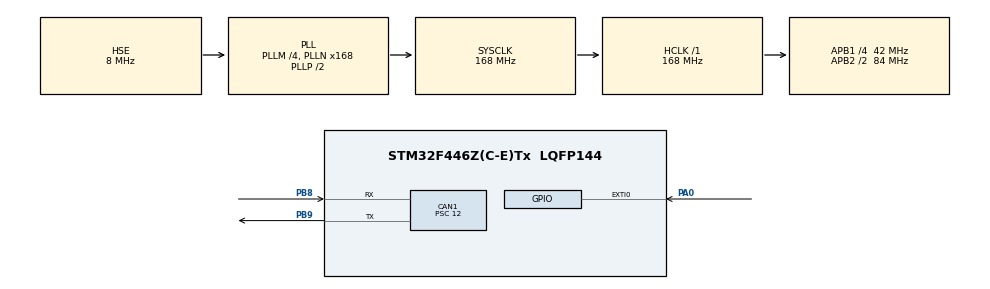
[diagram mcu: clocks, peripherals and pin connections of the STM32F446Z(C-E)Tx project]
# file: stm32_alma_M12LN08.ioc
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CAN1.BS1=CAN_BS1_11TQ
CAN1.BS2=CAN_BS2_2TQ
CAN1.CalculateBaudRate=250000
CAN1.CalculateTimeBit=4000
CAN1.CalculateTimeQuantum=285.7142857142857
CAN1.Prescaler=12
Mcu.Family=STM32F4
Mcu.Name=STM32F446Z(C-E)Tx
Mcu.Package=LQFP144
NVIC.CAN1_RX0_IRQn=true\:0\:0\:false\:false\:true\:true\:true\:true
NVIC.EXTI0_IRQn=true\:0\:0\:false\:false\:true\:true\:true\:true
NVIC.PriorityGroup=NVIC_PRIORITYGROUP_0
PA0-WKUP.Signal=GPXTI0
PA13.Mode=Serial_Wire
PA13.Signal=SYS_JTMS-SWDIO
PA14.Mode=Serial_Wire
PA14.Signal=SYS_JTCK-SWCLK
PB8.Mode=CAN_Activate
PB8.Signal=CAN1_RX
PB9.Mode=CAN_Activate
PB9.Signal=CAN1_TX
PH0-OSC_IN.Mode=HSE-External-Oscillator
PH0-OSC_IN.Signal=RCC_OSC_IN
PH1-OSC_OUT.Mode=HSE-External-Oscillator
PH1-OSC_OUT.Signal=RCC_OSC_OUT
ProjectManager.HeapSize=0x200
ProjectManager.StackSize=0x400
ProjectManager.TargetToolchain=STM32CubeIDE
RCC.AHBFreq_Value=168000000
RCC.APB1CLKDivider=RCC_HCLK_DIV4
RCC.APB1Freq_Value=42000000
RCC.APB1TimFreq_Value=84000000
RCC.APB2CLKDivider=RCC_HCLK_DIV2
RCC.APB2Freq_Value=84000000
RCC.APB2TimFreq_Value=168000000
RCC.CortexFreq_Value=168000000
RCC.HCLKFreq_Value=168000000
RCC.HSE_VALUE=8000000
RCC.PLLM=4
RCC.PLLN=168
RCC.PLLSourceVirtual=RCC_PLLSOURCE_HSE
RCC.SYSCLKFreq_VALUE=168000000
RCC.SYSCLKSource=RCC_SYSCLKSOURCE_PLLCLK
RCC.USBFreq_Value=168000000
RCC.VCOOutputFreq_Value=336000000
board=custom

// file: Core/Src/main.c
/* USER CODE BEGIN Header */
/**
  ******************************************************************************
  * @file           : main.c
  * @brief          : Main program body
  ******************************************************************************
  * @attention
  *
  * Copyright (c) 2024 STMicroelectronics.
  * All rights reserved.
  *
  * This software is licensed under terms that can be found in the LICENSE file
  * in the root directory of this software component.
  * If no LICENSE file comes with this software, it is provided AS-IS.
  *
  ******************************************************************************
  */
/* USER CODE END Header */
#include "main.h"

/* USER CODE BEGIN PD */
CAN_FilterTypeDef sFilterConfig;

/* USER CODE END PD */

CAN_HandleTypeDef hcan1;

/* USER CODE BEGIN PV */
//CAN_TxHeaderTypeDef pTxHeader;
//CAN_RxHeaderTypeDef pRxHeader;
//
//unsigned char TxData[8];
//unsigned char RxData[8];
//
//uint32_t TxMailBox;
/* USER CODE END PV */

void SystemClock_Config(void);
static void MX_GPIO_Init(void);
static void MX_CAN1_Init(void);

/* USER CODE BEGIN 0 */
CAN_TxHeaderTypeDef pTxHeader;
CAN_RxHeaderTypeDef pRxHeader;

unsigned char TxData[8];
unsigned char RxData[8];

uint32_t TxMailBox;
/* USER CODE END 0 */

int main(void)
{

  /* MCU Configuration--------------------------------------------------------*/

  /* Reset of all peripherals, Initializes the Flash interface and the Systick. */
  HAL_Init();

  /* Configure the system clock */
  SystemClock_Config();

  /* Initialize all configured peripherals */
  MX_GPIO_Init();
  MX_CAN1_Init();
  /* USER CODE BEGIN 2 */
    // start can communication
  HAL_CAN_Start(&hcan1);
    // Activate interrupt

  /* Start the CAN peripheral */

  /* Activate CAN RX notification */
    // set transmit parameter
  pTxHeader.DLC =8; // 8 bit =1byte
  pTxHeader.IDE = CAN_ID_STD ;
  pTxHeader.RTR = CAN_RTR_DATA;
  pTxHeader.StdId = 0x0000;

	pRxHeader.StdId=0x0000;
	pRxHeader.DLC=8;
	pRxHeader.IDE=CAN_ID_STD;
	pRxHeader.RTR=CAN_RTR_DATA;

  if (HAL_CAN_ActivateNotification(&hcan1, CAN_IT_RX_FIFO0_MSG_PENDING) != HAL_OK)
  {
    Error_Handler();
  }
  sFilterConfig.FilterBank = 0;
  sFilterConfig.FilterMode = CAN_FILTERMODE_IDMASK;
  sFilterConfig.FilterScale = CAN_FILTERSCALE_32BIT;
  sFilterConfig.FilterIdHigh = 0x0000;
  sFilterConfig.FilterIdLow = 0x0000 ;
  sFilterConfig.FilterMaskIdHigh =0x0000; // 0xFFF0- 0x0150 dersek yine aynı şeyi yapar
  sFilterConfig.FilterMaskIdLow = 0x0000;
  sFilterConfig.FilterFIFOAssignment = CAN_RX_FIFO0;
  sFilterConfig.FilterActivation = ENABLE;
  HAL_CAN_ActivateNotification(&hcan1, CAN_IT_RX_FIFO0_MSG_PENDING);
  if (HAL_CAN_ConfigFilter(&hcan1, &sFilterConfig) != HAL_OK)
  {
    Error_Handler();
  }
  HAL_CAN_ConfigFilter(&hcan1, &sFilterConfig);

  /* USER CODE END 2 */

  /* Infinite loop */
  while (1)
  {

    /* USER CODE BEGIN 3 */

	  HAL_CAN_GetRxMessage(&hcan1, CAN_RX_FIFO0 , &pRxHeader, RxData);

  }
  /* USER CODE END 3 */
}

void SystemClock_Config(void)
{
  RCC_OscInitTypeDef RCC_OscInitStruct = {0};
  RCC_ClkInitTypeDef RCC_ClkInitStruct = {0};

  /** Configure the main internal regulator output voltage
  */
  __HAL_RCC_PWR_CLK_ENABLE();
  __HAL_PWR_VOLTAGESCALING_CONFIG(PWR_REGULATOR_VOLTAGE_SCALE1);

  /** Initializes the RCC Oscillators according to the specified parameters
  * in the RCC_OscInitTypeDef structure.
  */
  RCC_OscInitStruct.OscillatorType = RCC_OSCILLATORTYPE_HSE;
  RCC_OscInitStruct.HSEState = RCC_HSE_ON;
  RCC_OscInitStruct.PLL.PLLState = RCC_PLL_ON;
  RCC_OscInitStruct.PLL.PLLSource = RCC_PLLSOURCE_HSE;
  RCC_OscInitStruct.PLL.PLLM = 4;
  RCC_OscInitStruct.PLL.PLLN = 168;
  RCC_OscInitStruct.PLL.PLLP = RCC_PLLP_DIV2;
  RCC_OscInitStruct.PLL.PLLQ = 2;
  RCC_OscInitStruct.PLL.PLLR = 2;
  if (HAL_RCC_OscConfig(&RCC_OscInitStruct) != HAL_OK)
  {
    Error_Handler();
  }

  /** Initializes the CPU, AHB and APB buses clocks
  */
  RCC_ClkInitStruct.ClockType = RCC_CLOCKTYPE_HCLK|RCC_CLOCKTYPE_SYSCLK
                              |RCC_CLOCKTYPE_PCLK1|RCC_CLOCKTYPE_PCLK2;
  RCC_ClkInitStruct.SYSCLKSource = RCC_SYSCLKSOURCE_PLLCLK;
  RCC_ClkInitStruct.AHBCLKDivider = RCC_SYSCLK_DIV1;
  RCC_ClkInitStruct.APB1CLKDivider = RCC_HCLK_DIV4;
  RCC_ClkInitStruct.APB2CLKDivider = RCC_HCLK_DIV2;

  if (HAL_RCC_ClockConfig(&RCC_ClkInitStruct, FLASH_LATENCY_5) != HAL_OK)
  {
    Error_Handler();
  }
}

static void MX_CAN1_Init(void)
{

  hcan1.Instance = CAN1;
  hcan1.Init.Prescaler = 12;
  hcan1.Init.Mode = CAN_MODE_NORMAL;
  hcan1.Init.SyncJumpWidth = CAN_SJW_1TQ;
  hcan1.Init.TimeSeg1 = CAN_BS1_11TQ;
  hcan1.Init.TimeSeg2 = CAN_BS2_2TQ;
  hcan1.Init.TimeTriggeredMode = DISABLE;
  hcan1.Init.AutoBusOff = DISABLE;
  hcan1.Init.AutoWakeUp = DISABLE;
  hcan1.Init.AutoRetransmission = DISABLE;
  hcan1.Init.ReceiveFifoLocked = DISABLE;
  hcan1.Init.TransmitFifoPriority = DISABLE;
  if (HAL_CAN_Init(&hcan1) != HAL_OK)
  {
    Error_Handler();
  }
  /* USER CODE BEGIN CAN1_Init 2 */
  /* USER CODE BEGIN CAN1_Init 2 */
	sFilterConfig.FilterBank = 0;                            // value between 0 to 13 for JUST Master Mode (CAN1)
	sFilterConfig.FilterMode = CAN_FILTERMODE_IDMASK;       // for filtering Identifiers
	sFilterConfig.FilterScale = CAN_FILTERSCALE_32BIT;     // for Scaling filtering (if use EXTENDED CAN this must be 32BIT)
	sFilterConfig.FilterIdHigh =0;         				  // First Identifier MSB value for receiving in IDLIST Mode for 32BIT Scaling
	sFilterConfig.FilterIdLow = 0;                   	 // First Identifier LSB value for receiving in IDLIST Mode for 32BIT Scaling
	sFilterConfig.FilterMaskIdHigh = 0;                 // Second Identifier MSB value for receiving in IDLIST Mode for 32BIT Scaling
	sFilterConfig.FilterMaskIdLow = 0;                 // Second Identifier LSB value for receiving in IDLIST Mode for 32BIT Scaling
	sFilterConfig.FilterFIFOAssignment = CAN_RX_FIFO0;// specify FIFO0 or FIFO1
	sFilterConfig.FilterActivation = ENABLE;		 // Enable filtering
	sFilterConfig.SlaveStartFilterBank = 14;
	  if (HAL_CAN_ConfigFilter(&hcan1, &sFilterConfig) != HAL_OK)
	  {
	    Error_Handler();
	  }
  /* USER CODE END CAN1_Init 2 */

}

static void MX_GPIO_Init(void)
{
  GPIO_InitTypeDef GPIO_InitStruct = {0};

  /* GPIO Ports Clock Enable */
  __HAL_RCC_GPIOH_CLK_ENABLE();
  __HAL_RCC_GPIOA_CLK_ENABLE();
  __HAL_RCC_GPIOB_CLK_ENABLE();

  /*Configure GPIO pin : PA0 */
  GPIO_InitStruct.Pin = GPIO_PIN_0;
  GPIO_InitStruct.Mode = GPIO_MODE_IT_RISING;
  GPIO_InitStruct.Pull = GPIO_NOPULL;
  HAL_GPIO_Init(GPIOA, &GPIO_InitStruct);

  /* EXTI interrupt init*/
  HAL_NVIC_SetPriority(EXTI0_IRQn, 0, 0);
  HAL_NVIC_EnableIRQ(EXTI0_IRQn);

}

/* USER CODE BEGIN 4 */
void HAL_CAN_RxFifo0MsgPendingCallback(CAN_HandleTypeDef *hcan)
{
	if (HAL_CAN_GetRxMessage(&hcan1, CAN_RX_FIFO0 , &pRxHeader, RxData) == HAL_OK)
  {
    // Handle received message
  }
}
/* USER CODE END 4 */

void Error_Handler(void)
{
	__disable_irq();
	while (1)
	{
	}
}
